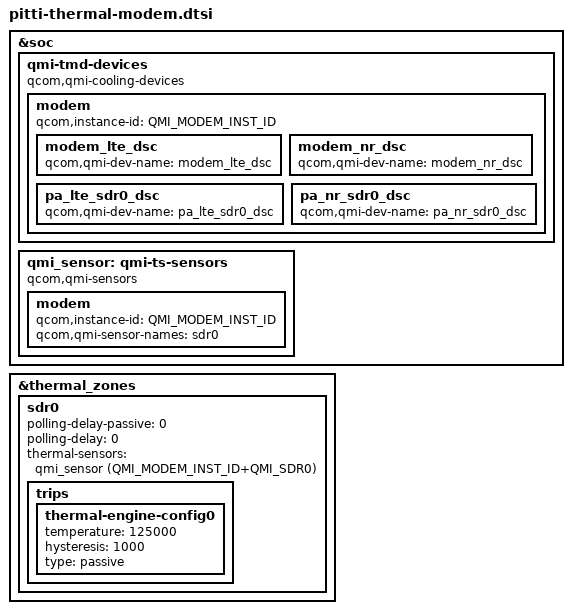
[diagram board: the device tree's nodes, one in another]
#include <dt-bindings/thermal/thermal_qti.h>

&soc {
	qmi-tmd-devices {
		compatible = "qcom,qmi-cooling-devices";

		modem {
			qcom,instance-id = <QMI_MODEM_INST_ID>;

			modem_lte_dsc: modem_lte_dsc {
				qcom,qmi-dev-name = "modem_lte_dsc";
				#cooling-cells = <2>;
			};

			modem_nr_dsc: modem_nr_dsc {
				qcom,qmi-dev-name = "modem_nr_dsc";
				#cooling-cells = <2>;
			};

			pa_lte_sdr0_dsc: pa_lte_sdr0_dsc {
				qcom,qmi-dev-name = "pa_lte_sdr0_dsc";
				#cooling-cells = <2>;
			};


			pa_nr_sdr0_dsc: pa_nr_sdr0_dsc {
				qcom,qmi-dev-name = "pa_nr_sdr0_dsc";
				#cooling-cells = <2>;
			};
		};
	};

	qmi_sensor: qmi-ts-sensors {
		compatible = "qcom,qmi-sensors";
		#thermal-sensor-cells = <1>;

		modem {
			qcom,instance-id = <QMI_MODEM_INST_ID>;
			qcom,qmi-sensor-names = "sdr0";
		};
	};
};

&thermal_zones {
	sdr0 {
		polling-delay-passive = <0>;
		polling-delay = <0>;
		thermal-sensors = <&qmi_sensor
				(QMI_MODEM_INST_ID+QMI_SDR0)>;
		trips {
			thermal-engine-config0 {
				temperature = <125000>;
				hysteresis = <1000>;
				type = "passive";
			};
		};
	};
};
